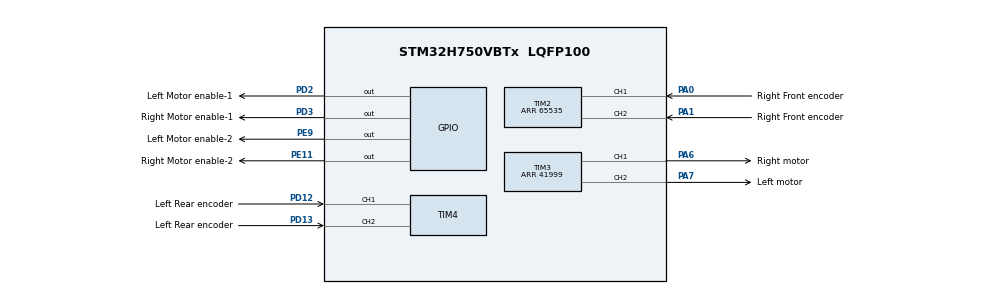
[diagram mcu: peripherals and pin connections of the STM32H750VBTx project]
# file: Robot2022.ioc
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CORTEX_M7.default_mode_Activation=1
Mcu.Family=STM32H7
Mcu.Name=STM32H750VBTx
Mcu.Package=LQFP100
NVIC.PriorityGroup=NVIC_PRIORITYGROUP_4
NVIC.TIM2_IRQn=true\:0\:0\:false\:false\:true\:true\:true\:true
NVIC.TIM4_IRQn=true\:0\:0\:false\:false\:true\:true\:true\:true
PA0.GPIO_Label=Right Front encoder
PA0.Signal=S_TIM2_CH1_ETR
PA1.GPIO_Label=Right Front encoder
PA1.Signal=S_TIM2_CH2
PA6.GPIO_Label=Right motor
PA6.GPIO_PuPd=GPIO_PULLUP
PA6.GPIO_Speed=GPIO_SPEED_FREQ_HIGH
PA6.Signal=S_TIM3_CH1
PA7.GPIO_Label=Left motor
PA7.GPIO_PuPd=GPIO_PULLUP
PA7.GPIO_Speed=GPIO_SPEED_FREQ_HIGH
PA7.Signal=S_TIM3_CH2
PD12.GPIO_Label=Left Rear encoder
PD12.Signal=S_TIM4_CH1
PD13.GPIO_Label=Left Rear encoder
PD13.Signal=S_TIM4_CH2
PD2.GPIO_Label=Left Motor enable-1
PD2.GPIO_PuPd=GPIO_PULLUP
PD2.GPIO_Speed=GPIO_SPEED_FREQ_HIGH
PD2.Signal=GPIO_Output
PD3.GPIO_Label=Right Motor enable-1
PD3.GPIO_PuPd=GPIO_PULLUP
PD3.GPIO_Speed=GPIO_SPEED_FREQ_HIGH
PD3.Signal=GPIO_Output
PE11.GPIO_Label=Right Motor enable-2
PE11.GPIO_PuPd=GPIO_PULLUP
PE11.GPIO_Speed=GPIO_SPEED_FREQ_HIGH
PE11.Signal=GPIO_Output
PE9.GPIO_Label=Left Motor enable-2
PE9.GPIO_PuPd=GPIO_PULLUP
PE9.GPIO_Speed=GPIO_SPEED_FREQ_HIGH
PE9.Signal=GPIO_Output
PH0-OSC_IN\ (PH0).Mode=HSE-External-Oscillator
PH0-OSC_IN\ (PH0).Signal=RCC_OSC_IN
PH1-OSC_OUT\ (PH1).Mode=HSE-External-Oscillator
PH1-OSC_OUT\ (PH1).Signal=RCC_OSC_OUT
ProjectManager.HeapSize=0x200
ProjectManager.StackSize=0x400
ProjectManager.TargetToolchain=MDK-ARM V5.32
RCC.ADCFreq_Value=16125000
RCC.APB1Freq_Value=37500000
RCC.APB2Freq_Value=37500000
RCC.APB3Freq_Value=37500000
RCC.APB4Freq_Value=37500000
RCC.CortexFreq_Value=75000000
RCC.DIVM1=1
RCC.DIVN1=18
RCC.HCLKFreq_Value=37500000
RCC.HPRE=RCC_HCLK_DIV2
RCC.HSE_VALUE=8000000
RCC.PLLFRACN=6144
RCC.PLLSourceVirtual=RCC_PLLSOURCE_HSE
RCC.SYSCLKFreq_VALUE=75000000
RCC.SYSCLKSource=RCC_SYSCLKSOURCE_PLLCLK
RCC.USBFreq_Value=75000000
SH.S_TIM2_CH1_ETR.0=TIM2_CH1,Encoder_Interface
SH.S_TIM2_CH2.0=TIM2_CH2,Encoder_Interface
SH.S_TIM3_CH1.0=TIM3_CH1,PWM Generation1 CH1
SH.S_TIM3_CH2.0=TIM3_CH2,PWM Generation2 CH2
SH.S_TIM4_CH1.0=TIM4_CH1,Encoder_Interface
SH.S_TIM4_CH2.0=TIM4_CH2,Encoder_Interface
TIM2.EncoderMode=TIM_ENCODERMODE_TI12
TIM2.Period=65535
TIM3.AutoReloadPreload=TIM_AUTORELOAD_PRELOAD_ENABLE
TIM3.Channel-PWM\ Generation1\ CH1=TIM_CHANNEL_1
TIM3.Channel-PWM\ Generation2\ CH2=TIM_CHANNEL_2
TIM3.Period=41999
TIM4.EncoderMode=TIM_ENCODERMODE_TI12
board=custom

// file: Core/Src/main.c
/* USER CODE BEGIN Header */
/**
  ******************************************************************************
  * @file           : main.c
  * @brief          : Main program body
  ******************************************************************************
  * @attention
  *
  * Copyright (c) 2022 STMicroelectronics.
  * All rights reserved.
  *
  * This software is licensed under terms that can be found in the LICENSE file
  * in the root directory of this software component.
  * If no LICENSE file comes with this software, it is provided AS-IS.
  *
  ******************************************************************************
  */
/* USER CODE END Header */
#include "main.h"
#include "tim.h"
#include "gpio.h"

/* USER CODE BEGIN Includes */
#include "stdio.h"
#include "math.h"
/* USER CODE END Includes */

void SystemClock_Config(void);
static void MPU_Config(void);

int main(void)
{

  /* MPU Configuration--------------------------------------------------------*/
  MPU_Config();

  /* MCU Configuration--------------------------------------------------------*/

  /* Reset of all peripherals, Initializes the Flash interface and the Systick. */
  HAL_Init();

  /* Configure the system clock */
  SystemClock_Config();

  /* Initialize all configured peripherals */
  MX_GPIO_Init();
  MX_TIM2_Init();
  MX_TIM3_Init();
  MX_TIM4_Init();

  /* Infinite loop */
  while (1)
  {

  }
}

void SystemClock_Config(void)
{
  RCC_OscInitTypeDef RCC_OscInitStruct = {0};
  RCC_ClkInitTypeDef RCC_ClkInitStruct = {0};

  /** Supply configuration update enable
  */
  HAL_PWREx_ConfigSupply(PWR_LDO_SUPPLY);

  /** Configure the main internal regulator output voltage
  */
  __HAL_PWR_VOLTAGESCALING_CONFIG(PWR_REGULATOR_VOLTAGE_SCALE3);

  while(!__HAL_PWR_GET_FLAG(PWR_FLAG_VOSRDY)) {}

  /** Initializes the RCC Oscillators according to the specified parameters
  * in the RCC_OscInitTypeDef structure.
  */
  RCC_OscInitStruct.OscillatorType = RCC_OSCILLATORTYPE_HSE;
  RCC_OscInitStruct.HSEState = RCC_HSE_ON;
  RCC_OscInitStruct.PLL.PLLState = RCC_PLL_ON;
  RCC_OscInitStruct.PLL.PLLSource = RCC_PLLSOURCE_HSE;
  RCC_OscInitStruct.PLL.PLLM = 1;
  RCC_OscInitStruct.PLL.PLLN = 18;
  RCC_OscInitStruct.PLL.PLLP = 2;
  RCC_OscInitStruct.PLL.PLLQ = 2;
  RCC_OscInitStruct.PLL.PLLR = 2;
  RCC_OscInitStruct.PLL.PLLRGE = RCC_PLL1VCIRANGE_3;
  RCC_OscInitStruct.PLL.PLLVCOSEL = RCC_PLL1VCOMEDIUM;
  RCC_OscInitStruct.PLL.PLLFRACN = 6144;
  if (HAL_RCC_OscConfig(&RCC_OscInitStruct) != HAL_OK)
  {
    Error_Handler();
  }

  /** Initializes the CPU, AHB and APB buses clocks
  */
  RCC_ClkInitStruct.ClockType = RCC_CLOCKTYPE_HCLK|RCC_CLOCKTYPE_SYSCLK
                              |RCC_CLOCKTYPE_PCLK1|RCC_CLOCKTYPE_PCLK2
                              |RCC_CLOCKTYPE_D3PCLK1|RCC_CLOCKTYPE_D1PCLK1;
  RCC_ClkInitStruct.SYSCLKSource = RCC_SYSCLKSOURCE_PLLCLK;
  RCC_ClkInitStruct.SYSCLKDivider = RCC_SYSCLK_DIV1;
  RCC_ClkInitStruct.AHBCLKDivider = RCC_HCLK_DIV2;
  RCC_ClkInitStruct.APB3CLKDivider = RCC_APB3_DIV1;
  RCC_ClkInitStruct.APB1CLKDivider = RCC_APB1_DIV1;
  RCC_ClkInitStruct.APB2CLKDivider = RCC_APB2_DIV1;
  RCC_ClkInitStruct.APB4CLKDivider = RCC_APB4_DIV1;

  if (HAL_RCC_ClockConfig(&RCC_ClkInitStruct, FLASH_LATENCY_0) != HAL_OK)
  {
    Error_Handler();
  }
}

/* MPU Configuration */

void MPU_Config(void)
{
  MPU_Region_InitTypeDef MPU_InitStruct = {0};

  /* Disables the MPU */
  HAL_MPU_Disable();

  /** Initializes and configures the Region and the memory to be protected
  */
  MPU_InitStruct.Enable = MPU_REGION_ENABLE;
  MPU_InitStruct.Number = MPU_REGION_NUMBER0;
  MPU_InitStruct.BaseAddress = 0x0;
  MPU_InitStruct.Size = MPU_REGION_SIZE_4GB;
  MPU_InitStruct.SubRegionDisable = 0x87;
  MPU_InitStruct.TypeExtField = MPU_TEX_LEVEL0;
  MPU_InitStruct.AccessPermission = MPU_REGION_NO_ACCESS;
  MPU_InitStruct.DisableExec = MPU_INSTRUCTION_ACCESS_DISABLE;
  MPU_InitStruct.IsShareable = MPU_ACCESS_SHAREABLE;
  MPU_InitStruct.IsCacheable = MPU_ACCESS_NOT_CACHEABLE;
  MPU_InitStruct.IsBufferable = MPU_ACCESS_NOT_BUFFERABLE;

  HAL_MPU_ConfigRegion(&MPU_InitStruct);
  /* Enables the MPU */
  HAL_MPU_Enable(MPU_PRIVILEGED_DEFAULT);

}

void Error_Handler(void)
{
  __disable_irq();
  while (1)
  {
  }
}
